AUTOSAR XML (schema 4-0-3)
package /ComponentTypes
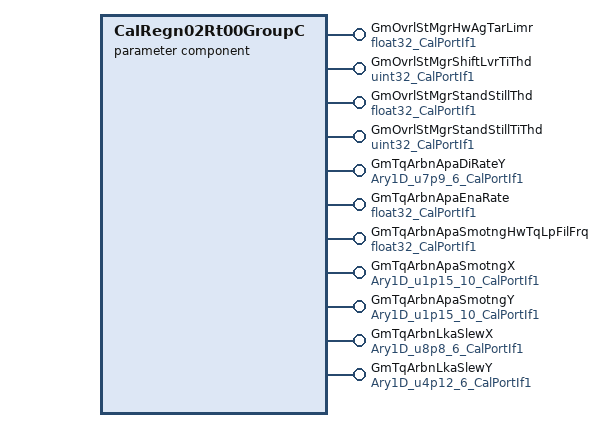
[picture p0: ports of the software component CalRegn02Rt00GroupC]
  parameter sw component type CalRegn02Rt00GroupC
    11 x provide port:
      GmOvrlStMgrHwAgTarLimr: parameter-provide-com-spec{init-value=30, parameter=Val}, provided-interface=float32_CalPortIf1
      GmOvrlStMgrShiftLvrTiThd: parameter-provide-com-spec{init-value=200, parameter=Val}, provided-interface=uint32_CalPortIf1
      GmOvrlStMgrStandStillThd: parameter-provide-com-spec{init-value=2.5, parameter=Val}, provided-interface=float32_CalPortIf1
      GmOvrlStMgrStandStillTiThd: parameter-provide-com-spec{init-value=250, parameter=Val}, provided-interface=uint32_CalPortIf1
      GmTqArbnApaDiRateY: parameter-provide-com-spec{init-value=[154, 205, 256, 512, 1024, 2560], parameter=Ary1D}, provided-interface=Ary1D_u7p9_6_CalPortIf1
      GmTqArbnApaEnaRate: parameter-provide-com-spec{init-value=0.5, parameter=Val}, provided-interface=float32_CalPortIf1
      GmTqArbnApaSmotngHwTqLpFilFrq: parameter-provide-com-spec{init-value=3, parameter=Val}, provided-interface=float32_CalPortIf1
      GmTqArbnApaSmotngX: parameter-provide-com-spec{init-value=[0, 3277, 6554, 9830, 13107, 19661, 22938, 26214, 29491, 32768], parameter=Ary1D}, provided-interface=Ary1D_u1p15_10_CalPortIf1
      GmTqArbnApaSmotngY: parameter-provide-com-spec{init-value=[0, 786, 3113, 6750, 11305, 21463, 26018, 29655, 31982, 32768], parameter=Ary1D}, provided-interface=Ary1D_u1p15_10_CalPortIf1
      GmTqArbnLkaSlewX: parameter-provide-com-spec{init-value=[2560, 10240, 17920, 25600, 33280, 46080], parameter=Ary1D}, provided-interface=Ary1D_u8p8_6_CalPortIf1
      GmTqArbnLkaSlewY: parameter-provide-com-spec{init-value=6 x 12288, parameter=Ary1D}, provided-interface=Ary1D_u4p12_6_CalPortIf1
